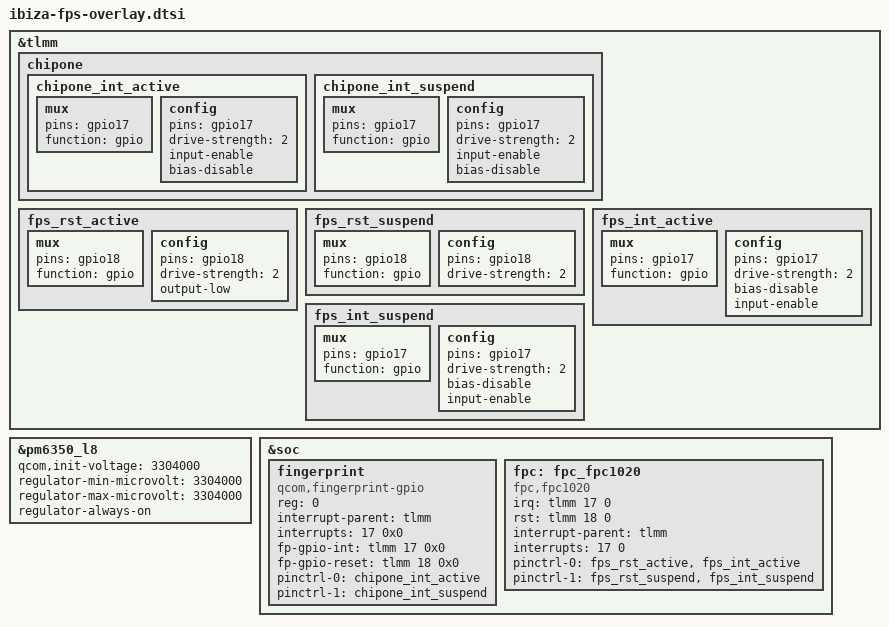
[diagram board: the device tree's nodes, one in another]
&tlmm {
	chipone {
		chipone_int_active: chipone_int_active {
			/* INTERRUPT */
			mux {
				pins = "gpio17";
				function = "gpio";
			};

			config {
				pins = "gpio17";
				drive-strength = <2>; /* 2 MA */
				input-enable;
				bias-disable;
			};
		};
		chipone_int_suspend: chipone_int_suspend {
			/* INTERRUPT */
			mux {
				pins = "gpio17";
				function = "gpio";
			};

			config {
				pins = "gpio17";
				drive-strength = <2>; /* 2 MA */
				input-enable;
				bias-disable;
			};
		};
	};

	fps_rst_active: fps_rst_active {
		/* active state */
		mux {
			pins = "gpio18";
			function = "gpio";
		};

		config {
			pins = "gpio18";
			drive-strength = <2>; /* 2 MA */
			output-low;
		};
	};

	fps_rst_suspend: fps_rst_suspend {
		/* sleep state */
		mux {
			pins = "gpio18";
			function = "gpio";
		};

		config {
			pins = "gpio18";
			drive-strength = <2>; /* 2 MA */
		};
	};

	fps_int_active: fps_int_active {
		/* active state */
		mux {
			pins = "gpio17";
			function = "gpio";
		};

		config {
			pins = "gpio17";
			drive-strength = <2>; /* 2 MA */
			bias-disable;
			input-enable;
		};
	};

	fps_int_suspend: fps_int_suspend {
		/* sleep state */
		mux {
			pins = "gpio17";
			function = "gpio";
		};

		config {
			pins = "gpio17";
			drive-strength = <2>; /* 2 MA */
			bias-disable;
			input-enable;
		};
	};
};

&pm6350_l8 {
 qcom,init-voltage = <3304000>;
 regulator-min-microvolt = <3304000>;
 regulator-max-microvolt = <3304000>;
 regulator-always-on;
};

&soc {
	fingerprint {
		compatible = "qcom,fingerprint-gpio";
		status = "ok";
		reg = <0>;
		interrupt-parent = <&tlmm>;
		interrupts = <17 0x0>;
		fp-gpio-int = <&tlmm 17 0x0>;
		fp-gpio-reset = <&tlmm 18 0x0>;
		pinctrl-names = "default", "suspend";
		pinctrl-0 = <&chipone_int_active>;
		pinctrl-1 = <&chipone_int_suspend>;
	};

	fpc: fpc_fpc1020 {
		compatible = "fpc,fpc1020";
		status = "ok";
		irq = <&tlmm 17 0>;
		rst = <&tlmm 18 0>;
		interrupt-parent = <&tlmm>;
		interrupts = <17 0>;
		pinctrl-names = "default", "suspend";
		pinctrl-0 = <&fps_rst_active &fps_int_active>;
		pinctrl-1 = <&fps_rst_suspend &fps_int_suspend>;
	};
};
